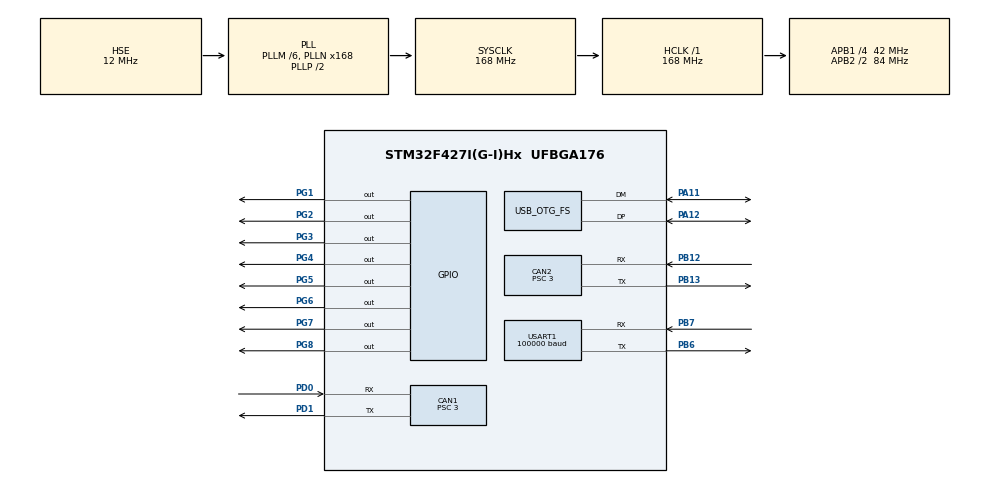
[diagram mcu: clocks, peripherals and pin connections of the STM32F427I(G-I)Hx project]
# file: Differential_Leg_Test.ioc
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CAN1.ABOM=ENABLE
CAN1.AWUM=ENABLE
CAN1.BS1=CAN_BS1_6TQ
CAN1.BS2=CAN_BS2_7TQ
CAN1.CalculateBaudRate=1000000
CAN1.CalculateTimeBit=1000
CAN1.CalculateTimeQuantum=71.42857142857143
CAN1.NART=ENABLE
CAN1.Prescaler=3
CAN1.SJW=CAN_SJW_4TQ
CAN2.ABOM=ENABLE
CAN2.AWUM=ENABLE
CAN2.BS1=CAN_BS1_6TQ
CAN2.BS2=CAN_BS2_7TQ
CAN2.CalculateBaudRate=1000000
CAN2.CalculateTimeBit=1000
CAN2.CalculateTimeQuantum=71.42857142857143
CAN2.NART=ENABLE
CAN2.Prescaler=3
Dma.Request0=USART1_RX
Dma.USART1_RX.0.Direction=DMA_PERIPH_TO_MEMORY
Dma.USART1_RX.0.FIFOMode=DMA_FIFOMODE_DISABLE
Dma.USART1_RX.0.Instance=DMA2_Stream2
Dma.USART1_RX.0.MemDataAlignment=DMA_MDATAALIGN_BYTE
Dma.USART1_RX.0.MemInc=DMA_MINC_ENABLE
Dma.USART1_RX.0.Mode=DMA_NORMAL
Dma.USART1_RX.0.PeriphDataAlignment=DMA_PDATAALIGN_BYTE
Dma.USART1_RX.0.PeriphInc=DMA_PINC_DISABLE
Dma.USART1_RX.0.Priority=DMA_PRIORITY_HIGH
Mcu.Family=STM32F4
Mcu.Name=STM32F427I(G-I)Hx
Mcu.Package=UFBGA176
NVIC.CAN1_RX0_IRQn=true\:1\:0\:true\:false\:true\:true\:true\:true
NVIC.CAN2_RX1_IRQn=true\:1\:0\:true\:false\:true\:true\:true\:true
NVIC.DMA2_Stream2_IRQn=true\:4\:0\:true\:false\:true\:false\:true\:true
NVIC.OTG_FS_IRQn=true\:0\:0\:true\:false\:true\:false\:true\:true
NVIC.PriorityGroup=NVIC_PRIORITYGROUP_4
NVIC.TIM2_IRQn=true\:2\:0\:true\:false\:true\:true\:true\:true
NVIC.TIM3_IRQn=true\:0\:0\:false\:false\:true\:true\:true\:true
NVIC.USART1_IRQn=true\:4\:0\:true\:false\:true\:true\:true\:true
PA11.Mode=Device_Only
PA11.Signal=USB_OTG_FS_DM
PA12.Mode=Device_Only
PA12.Signal=USB_OTG_FS_DP
PA13.Mode=Serial_Wire
PA13.Signal=SYS_JTMS-SWDIO
PA14.Mode=Serial_Wire
PA14.Signal=SYS_JTCK-SWCLK
PB12.GPIO_PuPd=GPIO_PULLUP
PB12.Mode=CAN_Activate
PB12.Signal=CAN2_RX
PB13.GPIO_PuPd=GPIO_PULLUP
PB13.Mode=CAN_Activate
PB13.Signal=CAN2_TX
PB6.GPIO_PuPd=GPIO_PULLUP
PB6.Mode=Asynchronous
PB6.Signal=USART1_TX
PB7.GPIO_PuPd=GPIO_PULLUP
PB7.Mode=Asynchronous
PB7.Signal=USART1_RX
PD0.GPIO_PuPd=GPIO_PULLUP
PD0.Mode=CAN_Activate
PD0.Signal=CAN1_RX
PD1.GPIO_PuPd=GPIO_PULLUP
PD1.Mode=CAN_Activate
PD1.Signal=CAN1_TX
PG1.GPIO_PuPd=GPIO_PULLUP
PG1.PinState=GPIO_PIN_SET
PG1.Signal=GPIO_Output
PG2.GPIO_PuPd=GPIO_PULLUP
PG2.PinState=GPIO_PIN_SET
PG2.Signal=GPIO_Output
PG3.GPIO_PuPd=GPIO_PULLUP
PG3.PinState=GPIO_PIN_SET
PG3.Signal=GPIO_Output
PG4.GPIO_PuPd=GPIO_PULLUP
PG4.PinState=GPIO_PIN_SET
PG4.Signal=GPIO_Output
PG5.GPIO_PuPd=GPIO_PULLUP
PG5.PinState=GPIO_PIN_SET
PG5.Signal=GPIO_Output
PG6.GPIO_PuPd=GPIO_PULLUP
PG6.PinState=GPIO_PIN_SET
PG6.Signal=GPIO_Output
PG7.GPIO_PuPd=GPIO_PULLUP
PG7.PinState=GPIO_PIN_SET
PG7.Signal=GPIO_Output
PG8.GPIO_PuPd=GPIO_PULLUP
PG8.PinState=GPIO_PIN_SET
PG8.Signal=GPIO_Output
PH0/OSC_IN.Mode=HSE-External-Oscillator
PH0/OSC_IN.Signal=RCC_OSC_IN
PH1/OSC_OUT.Mode=HSE-External-Oscillator
PH1/OSC_OUT.Signal=RCC_OSC_OUT
ProjectManager.HeapSize=0x600
ProjectManager.StackSize=0x600
ProjectManager.TargetToolchain=MDK-ARM V5.32
RCC.48MHZClocksFreq_Value=48000000
RCC.AHBFreq_Value=168000000
RCC.APB1CLKDivider=RCC_HCLK_DIV4
RCC.APB1Freq_Value=42000000
RCC.APB1TimFreq_Value=84000000
RCC.APB2CLKDivider=RCC_HCLK_DIV2
RCC.APB2Freq_Value=84000000
RCC.APB2TimFreq_Value=168000000
RCC.CortexFreq_Value=168000000
RCC.HCLKFreq_Value=168000000
RCC.HSE_VALUE=12000000
RCC.HSI_VALUE=16000000
RCC.LSE_VALUE=32768
RCC.PLLM=6
RCC.PLLN=168
RCC.PLLQ=7
RCC.SYSCLKFreq_VALUE=168000000
RCC.SYSCLKSource=RCC_SYSCLKSOURCE_PLLCLK
RCC.VCOOutputFreq_Value=336000000
TIM2.Period=999
TIM2.Prescaler=83
TIM3.Period=1999
TIM3.Prescaler=84
USART1.BaudRate=100000
USART1.Parity=PARITY_EVEN
USART1.VirtualMode=VM_ASYNC
USB_DEVICE.CLASS_NAME_FS=CUSTOM_HID
USB_DEVICE.CUSTOM_HID_FS_BINTERVAL=0x1
USB_DEVICE.PID_CUSTOMHID_FS=0x2222 
USB_DEVICE.VID-CUSTOM_HID_FS=0x1111
USB_DEVICE.VirtualMode-CUSTOM_HID_FS=CustomHid
USB_DEVICE.VirtualModeFS=Custom_Hid_FS
USB_OTG_FS.VirtualMode=Device_Only
VP_TIM2_VS_ClockSourceINT.Mode=Internal
VP_TIM3_VS_ClockSourceINT.Mode=Internal
VP_USB_DEVICE_VS_USB_DEVICE_CUSTOM_HID_FS.Mode=CUSTOM_HID_FS
board=custom

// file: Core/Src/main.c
/* USER CODE BEGIN Header */
/**
  ******************************************************************************
  * @file           : main.c
  * @brief          : Main program body
  ******************************************************************************
  * @attention
  *
  * Copyright (c) 2023 STMicroelectronics.
  * All rights reserved.
  *
  * This software is licensed under terms that can be found in the LICENSE file
  * in the root directory of this software component.
  * If no LICENSE file comes with this software, it is provided AS-IS.
  *
  ******************************************************************************
  */
/* USER CODE END Header */
#include "main.h"
#include "can.h"
#include "dma.h"
#include "tim.h"
#include "usart.h"
#include "usb_device.h"
#include "gpio.h"

/* USER CODE BEGIN Includes */
#include "processing_file.h"
#include "can_bldc_motor.h"
/* USER CODE END Includes */

void SystemClock_Config(void);

int main(void)
{

  /* MCU Configuration--------------------------------------------------------*/

  /* Reset of all peripherals, Initializes the Flash interface and the Systick. */
  HAL_Init();

  /* Configure the system clock */
  SystemClock_Config();

  /* Initialize all configured peripherals */
  MX_GPIO_Init();
  MX_DMA_Init();
  MX_USART1_UART_Init();
  MX_USB_DEVICE_Init();
  MX_CAN1_Init();
  MX_CAN2_Init();
  MX_TIM2_Init();
  MX_TIM3_Init();
  /* USER CODE BEGIN 2 */
	init_applications();
	Check_Motor_Status();
  /* USER CODE END 2 */

  /* Infinite loop */
  while (1)
  {
		//control_zero();
  }
}

void SystemClock_Config(void)
{
  RCC_OscInitTypeDef RCC_OscInitStruct = {0};
  RCC_ClkInitTypeDef RCC_ClkInitStruct = {0};

  /** Configure the main internal regulator output voltage
  */
  __HAL_RCC_PWR_CLK_ENABLE();
  __HAL_PWR_VOLTAGESCALING_CONFIG(PWR_REGULATOR_VOLTAGE_SCALE1);

  /** Initializes the RCC Oscillators according to the specified parameters
  * in the RCC_OscInitTypeDef structure.
  */
  RCC_OscInitStruct.OscillatorType = RCC_OSCILLATORTYPE_HSE;
  RCC_OscInitStruct.HSEState = RCC_HSE_ON;
  RCC_OscInitStruct.PLL.PLLState = RCC_PLL_ON;
  RCC_OscInitStruct.PLL.PLLSource = RCC_PLLSOURCE_HSE;
  RCC_OscInitStruct.PLL.PLLM = 6;
  RCC_OscInitStruct.PLL.PLLN = 168;
  RCC_OscInitStruct.PLL.PLLP = RCC_PLLP_DIV2;
  RCC_OscInitStruct.PLL.PLLQ = 7;
  if (HAL_RCC_OscConfig(&RCC_OscInitStruct) != HAL_OK)
  {
    Error_Handler();
  }

  /** Initializes the CPU, AHB and APB buses clocks
  */
  RCC_ClkInitStruct.ClockType = RCC_CLOCKTYPE_HCLK|RCC_CLOCKTYPE_SYSCLK
                              |RCC_CLOCKTYPE_PCLK1|RCC_CLOCKTYPE_PCLK2;
  RCC_ClkInitStruct.SYSCLKSource = RCC_SYSCLKSOURCE_PLLCLK;
  RCC_ClkInitStruct.AHBCLKDivider = RCC_SYSCLK_DIV1;
  RCC_ClkInitStruct.APB1CLKDivider = RCC_HCLK_DIV4;
  RCC_ClkInitStruct.APB2CLKDivider = RCC_HCLK_DIV2;

  if (HAL_RCC_ClockConfig(&RCC_ClkInitStruct, FLASH_LATENCY_5) != HAL_OK)
  {
    Error_Handler();
  }
}

/* USER CODE BEGIN 4 */
uint16_t leds[8] = {GPIO_PIN_8, GPIO_PIN_7, GPIO_PIN_6, GPIO_PIN_5, GPIO_PIN_4, GPIO_PIN_3, GPIO_PIN_2, GPIO_PIN_1};
/* USER CODE END 4 */

void Error_Handler(void)
{
  /* USER CODE BEGIN Error_Handler_Debug */
  /* User can add his own implementation to report the HAL error return state */
  __disable_irq();
  while (1)
  {
		for(int i = 0; i < 8; i++)
		 {
			 HAL_GPIO_WritePin(GPIOG, leds[i] , GPIO_PIN_RESET);
			 delay_ms(100);
			 HAL_GPIO_WritePin(GPIOG, leds[i] , GPIO_PIN_SET);
			 delay_ms(100);
		 }
  }
  /* USER CODE END Error_Handler_Debug */
}
